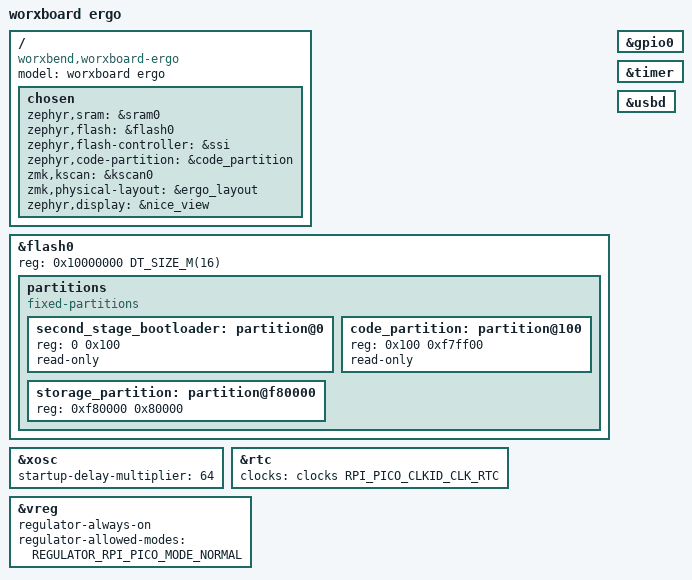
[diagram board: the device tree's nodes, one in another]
/* SPDX-License-Identifier: GPL-3.0-or-later */
/dts-v1/;
#include <raspberrypi/rpi_pico/rp2040.dtsi>
#include <arm/raspberrypi/rp2040-boot-mode-retention.dtsi>
#include <freq.h>
#include <zephyr/dt-bindings/gpio/gpio.h>
#include <zephyr/dt-bindings/pinctrl/rpi-pico-rp2040-pinctrl.h>
#include "worxboard-ergo-layout.dtsi"
#include "worxboard-ergo-pins.dtsi"
/ {
 model = "worxboard ergo";
 compatible = "worxbend,worxboard-ergo";
 chosen {
  zephyr,sram = &sram0;
  zephyr,flash = &flash0;
  zephyr,flash-controller = &ssi;
  zephyr,code-partition = &code_partition;
  zmk,kscan = &kscan0;
  zmk,physical-layout = &ergo_layout;
  zephyr,display = &nice_view;
 };
};
&flash0 {
 reg = <0x10000000 DT_SIZE_M(16)>;
 partitions {
  compatible = "fixed-partitions";
  #address-cells = <1>; #size-cells = <1>;
  second_stage_bootloader: partition@0 { reg = <0 0x100>; read-only; };
  code_partition: partition@100 { reg = <0x100 0xf7ff00>; read-only; };
  storage_partition: partition@f80000 { reg = <0xf80000 0x80000>; };
 };
};
&gpio0 { status = "okay"; };
&timer { status = "okay"; };
&xosc { startup-delay-multiplier = <64>; };
&rtc { clocks = <&clocks RPI_PICO_CLKID_CLK_RTC>; status = "okay"; };
&vreg { regulator-always-on; regulator-allowed-modes = <REGULATOR_RPI_PICO_MODE_NORMAL>; };
zephyr_udc0: &usbd { status = "okay"; };
